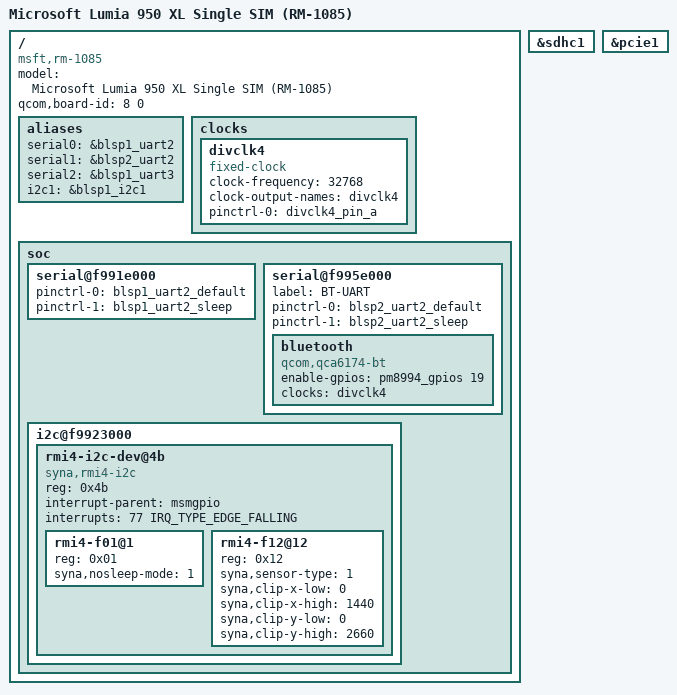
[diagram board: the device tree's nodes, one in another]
/* Copyright (c) 2016, The Linux Foundation. All rights reserved.
 * Copyright (c) 2018, Bingxing Wang. All rights reserved.
 *
 * This program is free software; you can redistribute it and/or modify
 * it under the terms of the GNU General Public License version 2 and
 * only version 2 as published by the Free Software Foundation.
 *
 * This program is distributed in the hope that it will be useful,
 * but WITHOUT ANY WARRANTY; without even the implied warranty of
 * MERCHANTABILITY or FITNESS FOR A PARTICULAR PURPOSE.  See the
 * GNU General Public License for more details.
 */

 /dts-v1/;

#include "msm8994.dtsi"
#include "pm8994.dtsi"
#include "pmi8994.dtsi"
#include "msm8994-microsoft-lumia-950xl-pmic-pins.dtsi"
#include <dt-bindings/gpio/gpio.h>

/ {
	model = "Microsoft Lumia 950 XL Single SIM (RM-1085)";
	compatible = "msft,rm-1085", "qcom,msm8994";
	/* Loading the dt via GRUB2. Not really care about this. */
	qcom,board-id = <8 0>;

	aliases {
		serial0 = &blsp1_uart2;
		serial1 = &blsp2_uart2;
		serial2 = &blsp1_uart3;
		i2c1 = &blsp1_i2c1;
	};

	clocks {
		divclk4: divclk4 {
			compatible = "fixed-clock";
			#clock-cells = <0>;
			clock-frequency = <32768>;
			clock-output-names = "divclk4";

			pinctrl-names = "default";
			pinctrl-0 = <&divclk4_pin_a>;
		};
	};

	soc {
		serial@f991e000 {
			status = "okay";
			pinctrl-names = "default", "sleep";
			pinctrl-0 = <&blsp1_uart2_default>;
			pinctrl-1 = <&blsp1_uart2_sleep>;
		};

		serial@f995e000 {
			label = "BT-UART";
			status = "okay";
			pinctrl-names = "default", "sleep";
			pinctrl-0 = <&blsp2_uart2_default>;
			pinctrl-1 = <&blsp2_uart2_sleep>;

			bluetooth {
				compatible = "qcom,qca6174-bt";

				/* bt_disable_n gpio */
				enable-gpios = <&pm8994_gpios 19 GPIO_ACTIVE_HIGH>;

				clocks = <&divclk4>;
			};
		};

		i2c@f9923000 {
			status = "okay";

			rmi4-i2c-dev@4b {
				compatible = "syna,rmi4-i2c";
				reg = <0x4b>;
				#address-cells = <1>;
				#size-cells = <0>;

				interrupt-parent = <&msmgpio>;
				interrupts = <77 IRQ_TYPE_EDGE_FALLING>;

				rmi4-f01@1 {
					reg = <0x01>;
					syna,nosleep-mode = <1>;
				};

				rmi4-f12@12 {
					reg = <0x12>;
					syna,sensor-type = <1>;
					syna,clip-x-low = <0>;
					syna,clip-x-high = <1440>;
					syna,clip-y-low = <0>;
					syna,clip-y-high = <2660>;
				};
			};
		};
	};
};

&sdhc1 {
	status = "okay";
};

&pcie1 {
	status = "okay";
};
